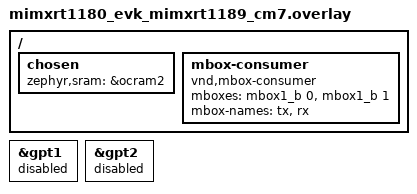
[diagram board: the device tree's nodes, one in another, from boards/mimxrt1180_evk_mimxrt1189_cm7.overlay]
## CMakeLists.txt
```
# Copyright 2026 NXP
# SPDX-License-Identifier: BSD-3-Clause

cmake_minimum_required(VERSION 3.20.0)

set(AppRootPath ${CMAKE_CURRENT_SOURCE_DIR})
set(AppCommonPath "${AppRootPath}/../common")
set(CommonPath "${AppRootPath}/../../../common")

# Common configuration fragment files
list(APPEND EXTRA_CONF_FILE
  "${CommonPath}/configs/base_secondary.conf"
  "${CommonPath}/configs/logging.conf"
  "${CommonPath}/configs/runtime-stats.conf"
)

# Load zephyr extensions to get BOARD for sysbuild and regular builds
find_package(Zephyr COMPONENTS extensions basic_settings REQUIRED HINTS $ENV{ZEPHYR_BASE})
zephyr_get(_TARGET_BOARD VAR BOARD)
# Common device tree overlays
if("${_TARGET_BOARD}" STREQUAL "mimxrt1180_evk/mimxrt1189/cm7")
  list(APPEND EXTRA_DTC_OVERLAY_FILE
    "../../../../zephyr/boards/nxp/mimxrt1180_evk/cm7_flash_boot.overlay"
    "${CommonPath}/overlays/nxp_rt118x_tune_interrupt_priorities.overlay"
  )
endif()

list(APPEND DTS_ROOT ${CMAKE_CURRENT_SOURCE_DIR}/../../..)

find_package(Zephyr REQUIRED HINTS $ENV{ZEPHYR_BASE})
project(tsn_init_secondary)
set(MCUX_SDK_PROJECT_NAME app)

if(NOT CONFIG_NXP_BOARD_SPECIFIC_MPU_SETTINGS)
  if(CONFIG_SOC_MIMXRT1189_CM7)
    zephyr_sources(${CommonPath}/soc/imxrt118x/cm7/mpu_regions.c)
  endif()
endif()


SET(HAL_NXP_PATH "${ZEPHYR_BASE}/../modules/hal/nxp")
SET(SdkRootDirPath "${HAL_NXP_PATH}/mcux/mcux-sdk-ng")

include(${CommonPath}/libs/sys_heap_stats/sys_heap_stats.cmake)

function(include_mcux_driver driver)
  set(CONFIG_MCUX_COMPONENT_driver.${driver} ON)
  include(${SdkRootDirPath}/drivers/${driver}/CMakeLists.txt)
endfunction()

if(CONFIG_BOARD_MIMXRT1180_EVK_MIMXRT1189_CM7)
  include_mcux_driver(rgpio)
  include_mcux_driver(gpt)
  set(CONFIG_MCUX_COMPONENT_driver.netc_rt1180 ON)
  include_mcux_driver(netc)
  include_mcux_driver(msgintr)
  set(BoardDir "evkmimxrt1180/cm7")
endif()

include (${CommonPath}/cmake/relocation.cmake)

include(genavb_sdk.cmake)

if(CONFIG_CODE_DATA_RELOCATION)

  file(GLOB_RECURSE APPS_SOURCES
    ${AppCommonPath}/*.c
    ${AppRootPath}/src/*.c
    ${CommonPath}/*.c
  )

  # Do not relocate early_mem.c file used for early memcpy and memset
  list(FILTER APPS_SOURCES EXCLUDE REGEX ".*/early_mem.c$")

  # NOINIT catches the system heap memory pool
  zephyr_code_relocate(FILES ${ZEPHYR_KERNEL_SOURCES} ${ZEPHYR_ARCH_SOURCES} ${ZEPHYR_LIB_SOURCES} LOCATION DTCM_DATA_BSS_NOINIT NOKEEP)
  zephyr_code_relocate(FILES ${ZEPHYR_KERNEL_SOURCES} ${ZEPHYR_ARCH_SOURCES} ${ZEPHYR_LIB_SOURCES} LOCATION ITCM_TEXT_RODATA NOKEEP)

  zephyr_code_relocate(FILES ${ZEPHYR_DRIVER_SOURCES} ${ZEPHYR_SUBSYS_SOURCES} ${APPS_SOURCES} ${MCU_SDK_SOURCES} LOCATION DTCM_DATA_BSS NOKEEP)
  zephyr_code_relocate(FILES ${ZEPHYR_DRIVER_SOURCES} ${ZEPHYR_SUBSYS_SOURCES} ${APPS_SOURCES} ${MCU_SDK_SOURCES} LOCATION ITCM_TEXT_RODATA NOKEEP)

endif()

zephyr_linker_sources(ITCM_SECTION ${CommonPath}/linker/libc_itcm.ld)
zephyr_linker_sources(ITCM_SECTION ${CommonPath}/linker/fsl_mem_ops.ld)
zephyr_linker_sources(ITCM_SECTION ${CommonPath}/linker/sw_isr_table.ld)

if(CONFIG_APP_TSN_BUILD_PROFILE_DEFAULT)
  zephyr_compile_definitions_ifdef(CONFIG_BOARD_MIMXRT1180_EVK_MIMXRT1189_CM7 CONFIG_APP_EP_LOGICAL_PORT_LIST={0})
  zephyr_compile_definitions_ifdef(CONFIG_BOARD_MIMXRT1180_EVK_MIMXRT1189_CM7 CONFIG_APP_EP_NUM_PORTS=1)
endif()

set(RTOS_ABSTRACTION_LAYER_DIR "${ZEPHYR_BASE}/../rtos-abstraction-layer/zephyr")
set(RTOS_ABSTRACTION_LAYER_TARGET app)
include(${RTOS_ABSTRACTION_LAYER_DIR}/rtos_abstraction_layer.cmake)

set(RtosAppsPath "${ZEPHYR_BASE}/../rtos-apps")
set(RTOS_APPS_TARGET app)
# Import storage for stubs
include(${RtosAppsPath}/rtos_apps_storage.cmake)
include(${RtosAppsPath}/rtos_apps_log.cmake)

target_sources(app PRIVATE
  ${CommonPath}/src/boards/${BoardDir}/board.c
  ${CommonPath}/src/gavb_stack.c
  ${CommonPath}/src/early_mem.c
  ${CommonPath}/src/init_sync.c
  ${AppCommonPath}/system_config.c
  ${AppCommonPath}/shared_config.c
  src/configs.c
  src/main.c
)

zephyr_include_directories(
  ${CommonPath}/src/boards/${BoardDir}
  src/boards/${BoardDir}
  ${CommonPath}/src
  ${AppCommonPath}
)
```

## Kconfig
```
# Copyright 2026 NXP
# SPDX-License-Identifier: BSD-3-Clause

source "Kconfig.zephyr"

rsource "../../../common/libs/sys_heap_stats/Kconfig"

rsource "../../../common/configs/Kconfig.tsn_apps"

rsource "../Kconfig.multicore"

choice APP_TSN_BUILD_PROFILE
    prompt "TSN build profile options"
    default APP_TSN_BUILD_PROFILE_DEFAULT

    config APP_TSN_BUILD_PROFILE_DEFAULT
        bool "TSN Endpoint default profile"
        select APP_TSN_ENDPOINT

endchoice
```

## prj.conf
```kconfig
CONFIG_MBOX=y
CONFIG_EVENTS=y
CONFIG_TSN_MULTICORE=y

# RTOS Abstraction Layer dependencies
CONFIG_DYNAMIC_THREAD=y
CONFIG_DYNAMIC_THREAD_ALLOC=y
```

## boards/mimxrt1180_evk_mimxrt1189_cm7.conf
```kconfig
CONFIG_HEAP_MEM_POOL_SIZE=65536

CONFIG_BUILD_OUTPUT_HEX=y
CONFIG_SECOND_CORE_MCUX=y

CONFIG_CM7_BOOT_FROM_FLASH=y
```

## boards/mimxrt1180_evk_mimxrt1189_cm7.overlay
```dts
/*
 * Copyright 2026 NXP
 *
 * SPDX-License-Identifier: BSD-3-Clause
 */

 / {
	/* Make ocram2 as default RAM region for the CM7 core */
	chosen {
		zephyr,sram  = &ocram2;
	};

	mbox-consumer {
		compatible = "vnd,mbox-consumer";
		mboxes = <&mbox1_b 0>, <&mbox1_b 1>;
		mbox-names = "tx", "rx";
	};
};

/* Disable peripherals handled outside the Zephyr device model */
/delete-node/ &netc;

&gpt1 {
	status = "disabled";
};

&gpt2 {
	status = "disabled";
};
```

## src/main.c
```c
/*
 * Copyright 2026 NXP
 *
 * SPDX-License-Identifier: BSD-3-Clause
 */

#include <stdio.h>

#include <zephyr/kernel.h>

#include "gavb_stack.h"
#include "board.h"
#include "init_sync.h"

#define TSN_INIT_STACK_SIZE 3048
#define TSN_INIT_STACK_PRIO (K_LOWEST_THREAD_PRIO - 4)

K_THREAD_STACK_DEFINE(tsn_init_stack, TSN_INIT_STACK_SIZE);
struct k_thread tsn_init_thread;

static void tsn_init_main(void *p1, void *p2, void *p3)
{
    int rc;

    printk("Starting GenAVB/TSN stack: enter\n");

    rc = gavb_stack_init();
    if (rc < 0)
        goto exit;

    printk("Starting GenAVB/TSN stack: success\n");
    return;

exit:
    printk("Starting GenAVB/TSN stack: failed\n");
}

int main(void)
{
    k_tid_t thread_ret;

#if defined(CONFIG_TSN_MULTICORE_SECONDARY)
    if (init_sync_wait_for_stack_ready() < 0) {
        printk("init_sync_wait_for_stack_ready() failed\n");
        return -1;
    }
#else
#error "CONFIG_TSN_MULTICORE_SECONDARY must be defined"
#endif

    BOARD_Init();
    BOARD_InitNVIC();

    printk("Main: started\n");

    thread_ret = k_thread_create(&tsn_init_thread, tsn_init_stack, TSN_INIT_STACK_SIZE,
                &tsn_init_main, NULL, NULL, NULL,
                TSN_INIT_STACK_PRIO, 0, K_NO_WAIT);

    return 0;
}
```

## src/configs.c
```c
/*
 * Copyright 2022, 2024-2026 NXP
 *
 * SPDX-License-Identifier: BSD-3-Clause
 */

#include "gavb_stack.h"
#include "system_config.h"

/* The secondary core configuration is retrieved from shared memory
 * prior to stack initialization via shared_system_config_get().
 * Its default settings originate from m7_system_cfg on the primary core,
 * and may be overridden by filesystem attributes configured there (on the
 * primary core).
 */
struct net_config system_net_cfg[CONFIG_APP_LOGICAL_PORTS] = {0};
```
